# PIC32MX550F256L register map
Vendor: Microchip
Registers are 32-bit, read-write, reset 0x0 unless marked. A register's access mark holds for its fields unless they carry their own. Addresses are absolute, and some are shared; only a register's first bit layout is shown; [hi:lo] are bit positions; {n}, {i} and the like mark numbered series.

## CMP2
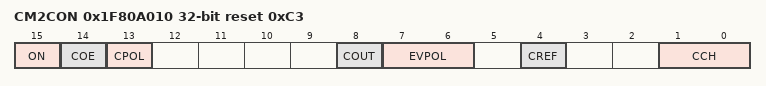
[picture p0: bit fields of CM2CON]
0x1F80A010 CM2CON reset 0xC3
  [15] ON, [14] COE, [13] CPOL, [8] COUT, [7:6] EVPOL, [4] CREF, [1:0] CCH

## CMP3
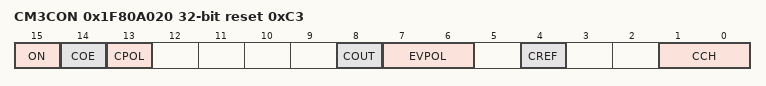
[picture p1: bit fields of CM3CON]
0x1F80A020 CM3CON reset 0xC3
  [15] ON, [14] COE, [13] CPOL, [8] COUT, [7:6] EVPOL, [4] CREF, [1:0] CCH

## cmp_control_pb
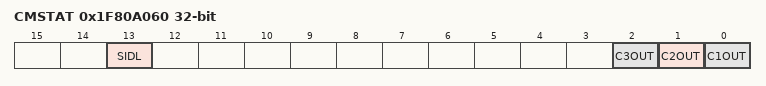
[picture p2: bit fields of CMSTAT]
0x1F80A060 CMSTAT reset not defined — (power-on value ------------------------00---x00)
  [13] SIDL, [2] C3OUT, [1] C2OUT ro, [0] C1OUT ro

## CTMU
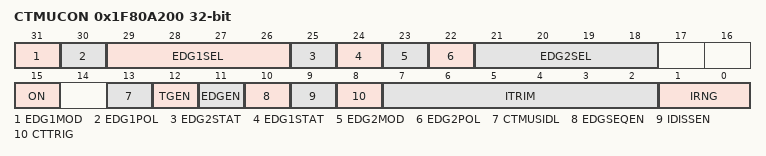
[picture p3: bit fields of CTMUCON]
0x1F80A200 CTMUCON
  [31] EDG1MOD, [30] EDG1POL, [29:26] EDG1SEL, [25] EDG2STAT, [24] EDG1STAT, [23] EDG2MOD, [22] EDG2POL, [21:18] EDG2SEL, [15] ON, [13] CTMUSIDL, [12] TGEN, [11] EDGEN, [10] EDGSEQEN, [9] IDISSEN, [8] CTTRIG, [7:2] ITRIM, [1:0] IRNG

## OSC
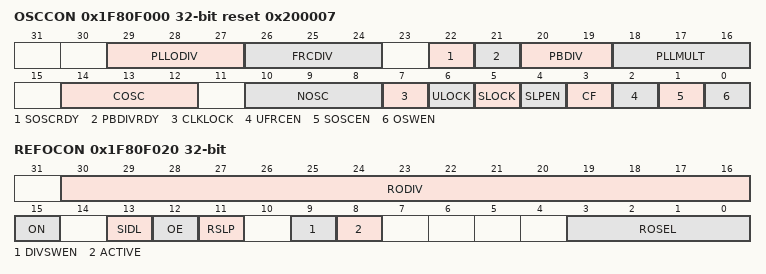
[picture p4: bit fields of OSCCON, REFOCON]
0x1F80F000 OSCCON reset 0x200007
  [29:27] PLLODIV, [26:24] FRCDIV, [22] SOSCRDY, [21] PBDIVRDY, [20:19] PBDIV, [18:16] PLLMULT, [14:12] COSC, [10:8] NOSC, [7] CLKLOCK, [6] ULOCK, [5] SLOCK, [4] SLPEN, [3] CF, [2] UFRCEN, [1] SOSCEN, [0] OSWEN
0x1F80F010 OSCTUN
  [5:0] TUN
0x1F80F020 REFOCON reset not defined — (power-on value -xxxxxxxxxxxxxxxxxxxxxxxx---xxxx)
  [30:16] RODIV, [15] ON, [13] SIDL, [12] OE, [11] RSLP, [9] DIVSWEN, [8] ACTIVE, [3:0] ROSEL
0x1F80F030 REFOTRIM reset not defined — (power-on value xxxxxxxxx-----------------------)
  [31:23] ROTRIM

## CFG
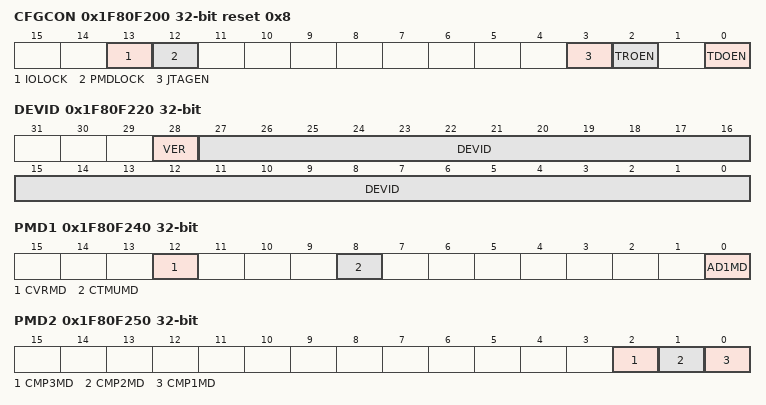
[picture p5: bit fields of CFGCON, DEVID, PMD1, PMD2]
0x1F80F200 CFGCON reset 0x8
  [13] IOLOCK, [12] PMDLOCK, [3] JTAGEN, [2] TROEN, [0] TDOEN
0x1F80F220 DEVID ro reset not defined — (power-on value xxxxxxxxxxxxxxxxxxxxxxxxxxxxxxxx)
  [28] VER, [27:0] DEVID
0x1F80F230 SYSKEY ro reset not defined — (power-on value xxxxxxxxxxxxxxxxxxxxxxxxxxxxxxxx)
0x1F80F240 PMD1
  [12] CVRMD, [8] CTMUMD, [0] AD1MD
0x1F80F250 PMD2
  [2] CMP3MD, [1] CMP2MD, [0] CMP1MD
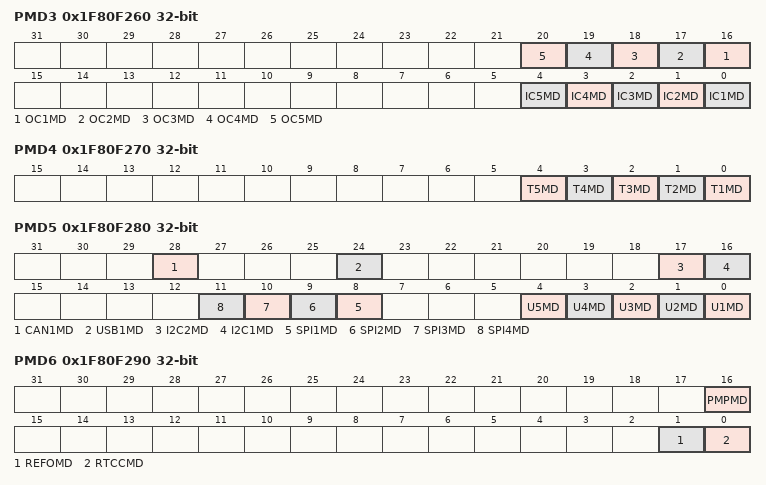
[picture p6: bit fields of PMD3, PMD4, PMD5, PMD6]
0x1F80F260 PMD3
  [n+15] OC{n}MD (n=1..5), [n-1] IC{n}MD (n=1..5)
0x1F80F270 PMD4
  [n-1] T{n}MD (n=1..5)
0x1F80F280 PMD5 reset not defined — (power-on value ---x---0------00----xx00---xxx00)
  [28] CAN1MD, [24] USB1MD, [17] I2C2MD, [16] I2C1MD, [n+7] SPI{n}MD (n=1..4), [n-1] U{n}MD (n=1..5)
0x1F80F290 PMD6
  [16] PMPMD, [1] REFOMD, [0] RTCCMD

## NVM
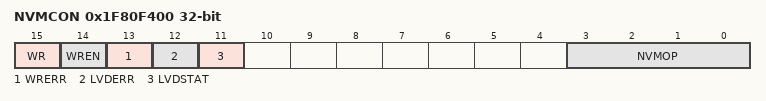
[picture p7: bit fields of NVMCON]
0x1F80F400 NVMCON
  [15] WR, [14] WREN, [13] WRERR, [12] LVDERR, [11] LVDSTAT, [3:0] NVMOP
0x1F80F410 NVMKEY wo
0x1F80F420 NVMADDR
0x1F80F430 NVMDATA
0x1F80F440 NVMSRCADDR

## RCON
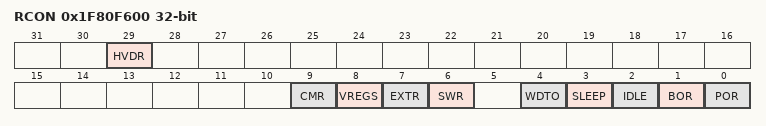
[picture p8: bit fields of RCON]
0x1F80F600 RCON reset not defined — (power-on value --x-------------------0000-00011)
  [29] HVDR, [9] CMR, [8] VREGS, [7] EXTR, [6] SWR, [4] WDTO, [3] SLEEP, [2] IDLE, [1] BOR, [0] POR
0x1F80F610 RSWRST
  [0] SWRST

## RPINRx
{0x1F80FA00+4i} INT{i}R (i=1..4)
  [3:0] INT{i}R
{0x1F80FA10+4i} T{i}CKR (i=2..5)
  [3:0] T{i}CKR
{0x1F80FA24+4i} IC{i}R (i=1..8)
  [3:0] IC{i}R
0x1F80FA48 OCFAR
  [3:0] OCFAR
0x1F80FA4C OCFBR
  [3:0] OCFBR
{0x1F80FA48+8i} U{i}RXR (i=1..6)
  [3:0] U{i}RXR
{0x1F80FA4C+8i} U{i}CTSR (i=1..6)
  [3:0] U{i}CTSR
{0x1F80FA78+0xC*i} SDI{i}R (i=1..6)
  [3:0] SDI{i}R
{0x1F80FA7C+0xC*i} SS{i}R (i=1..6)
  [3:0] SS{i}R
0x1F80FAC8 C1RXR
  [3:0] C1RXR
0x1F80FACC C2RXR
  [3:0] C2RXR
0x1F80FAD0 REFCLKIR
  [3:0] REFCLKIR
{0x1F80FACC+4i} REFI{i}R (i=2..4)
  [3:0] REFI{i}R

## RPORx
{0x1F80FB00+4i} RPA{i}R (i=0..15)
  [3:0] RPA{i}R
{0x1F80FB40+4i} RPB{i}R (i=0..15)
  [3:0] RPB{i}R
{0x1F80FB80+4i} RPC{i}R (i=0..15)
  [3:0] RPC{i}R
{0x1F80FBC0+4i} RPD{i}R (i=0..15)
  [3:0] RPD{i}R
{0x1F80FC00+4i} RPE{i}R (i=0..15)
  [3:0] RPE{i}R
{0x1F80FC40+4i} RPF{i}R (i=0..15)
  [3:0] RPF{i}R
{0x1F80FC80+4i} RPG{i}R (i=0..15)
  [3:0] RPG{i}R

## INT
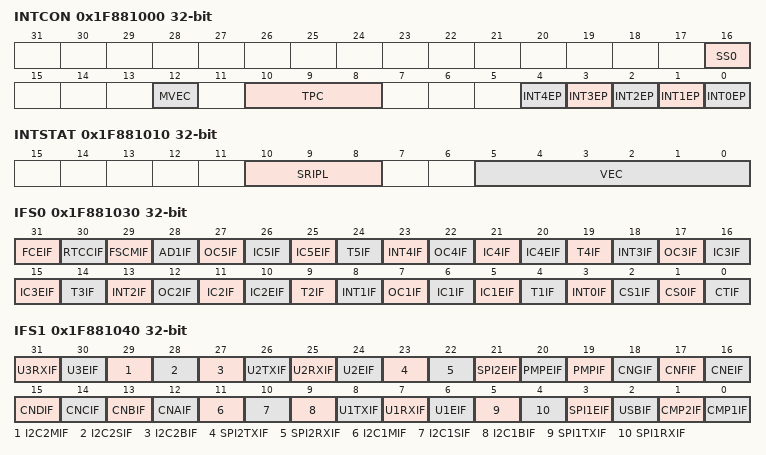
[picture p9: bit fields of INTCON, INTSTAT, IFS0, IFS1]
0x1F881000 INTCON
  [16] SS0, [12] MVEC, [10:8] TPC, [n] INT{n}EP (n=0..4)
0x1F881010 INTSTAT
  [10:8] SRIPL, [5:0] VEC
0x1F881020 IPTMR
0x1F881030 IFS0 reset not defined — (power-on value 00000x0000x0000x0000000000000000)
  [31] FCEIF, [30] RTCCIF, [29] FSCMIF, [28] AD1IF, [5n+2] OC{n}IF (n=1..5), [5n+1] IC{n}IF (n=1..5), [5n] IC{n}EIF (n=1..5), [5n-1] T{n}IF (n=1..5), [5n+3] INT{n}IF (n=0..4), [2] CS1IF, [1] CS0IF, [0] CTIF
0x1F881040 IFS1 reset not defined — (power-on value xxxxxx00xxxx00000000000000000000)
  [31] U3RXIF, [30] U3EIF, [29] I2C2MIF, [28] I2C2SIF, [27] I2C2BIF, [26] U2TXIF, [25] U2RXIF, [24] U2EIF, [23] SPI2TXIF, [22] SPI2RXIF, [21] SPI2EIF, [20] PMPEIF, [19] PMPIF, [18] CNGIF, [17] CNFIF, [16] CNEIF, [15] CNDIF, [14] CNCIF, [13] CNBIF, [12] CNAIF, [11] I2C1MIF, [10] I2C1SIF, [9] I2C1BIF, [8] U1TXIF, [7] U1RXIF, [6] U1EIF, [5] SPI1TXIF, [4] SPI1RXIF, [3] SPI1EIF, [2] USBIF, [1] CMP2IF, [0] CMP1IF
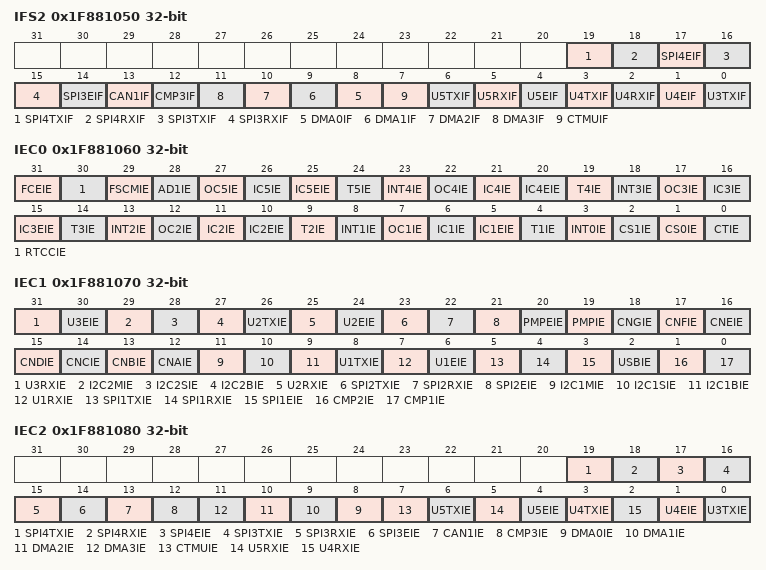
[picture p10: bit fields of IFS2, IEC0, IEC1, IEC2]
0x1F881050 IFS2
  [19] SPI4TXIF, [18] SPI4RXIF, [17] SPI4EIF, [16] SPI3TXIF, [15] SPI3RXIF, [14] SPI3EIF, [13] CAN1IF, [12] CMP3IF, [n+8] DMA{n}IF (n=0..3), [7] CTMUIF, [6] U5TXIF, [5] U5RXIF, [4] U5EIF, [3] U4TXIF, [2] U4RXIF, [1] U4EIF, [0] U3TXIF
0x1F881060 IEC0 reset not defined — (power-on value 00000x0000x0000x0000000000000000)
  [31] FCEIE, [30] RTCCIE, [29] FSCMIE, [28] AD1IE, [5n+2] OC{n}IE (n=1..5), [5n+1] IC{n}IE (n=1..5), [5n] IC{n}EIE (n=1..5), [5n-1] T{n}IE (n=1..5), [5n+3] INT{n}IE (n=0..4), [2] CS1IE, [1] CS0IE, [0] CTIE
0x1F881070 IEC1 reset not defined — (power-on value xxxxxx-0xxxx-0000000000000000000)
  [31] U3RXIE, [30] U3EIE, [29] I2C2MIE, [28] I2C2SIE, [27] I2C2BIE, [26] U2TXIE, [25] U2RXIE, [24] U2EIE, [23] SPI2TXIE, [22] SPI2RXIE, [21] SPI2EIE, [20] PMPEIE, [19] PMPIE, [18] CNGIE, [17] CNFIE, [16] CNEIE, [15] CNDIE, [14] CNCIE, [13] CNBIE, [12] CNAIE, [11] I2C1MIE, [10] I2C1SIE, [9] I2C1BIE, [8] U1TXIE, [7] U1RXIE, [6] U1EIE, [5] SPI1TXIE, [4] SPI1RXIE, [3] SPI1EIE, [2] USBIE, [1] CMP2IE, [0] CMP1IE
0x1F881080 IEC2
  [19] SPI4TXIE, [18] SPI4RXIE, [17] SPI4EIE, [16] SPI3TXIE, [15] SPI3RXIE, [14] SPI3EIE, [13] CAN1IE, [12] CMP3IE, [n+8] DMA{n}IE (n=0..3), [7] CTMUIE, [6] U5TXIE, [5] U5RXIE, [4] U5EIE, [3] U4TXIE, [2] U4RXIE, [1] U4EIE, [0] U3TXIE
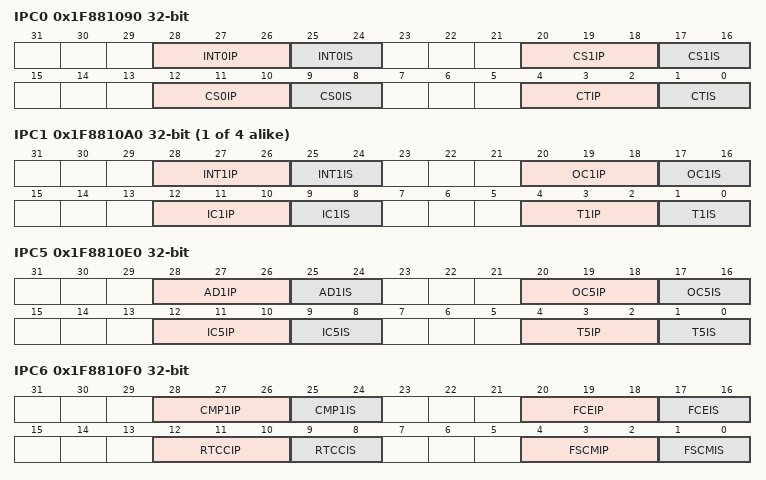
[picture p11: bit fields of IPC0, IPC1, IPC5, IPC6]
0x1F881090 IPC0
  [28:26] INT0IP, [25:24] INT0IS, [20:18] CS1IP, [17:16] CS1IS, [12:10] CS0IP, [9:8] CS0IS, [4:2] CTIP, [1:0] CTIS
{0x1F881090+0x10*i} IPC{i} (i=1..4)
  [28:26] INT{i}IP, [25:24] INT{i}IS, [20:18] OC{i}IP, [17:16] OC{i}IS, [12:10] IC{i}IP, [9:8] IC{i}IS, [4:2] T{i}IP, [1:0] T{i}IS
0x1F8810E0 IPC5
  [28:26] AD1IP, [25:24] AD1IS, [20:18] OC5IP, [17:16] OC5IS, [12:10] IC5IP, [9:8] IC5IS, [4:2] T5IP, [1:0] T5IS
0x1F8810F0 IPC6
  [28:26] CMP1IP, [25:24] CMP1IS, [20:18] FCEIP, [17:16] FCEIS, [12:10] RTCCIP, [9:8] RTCCIS, [4:2] FSCMIP, [1:0] FSCMIS
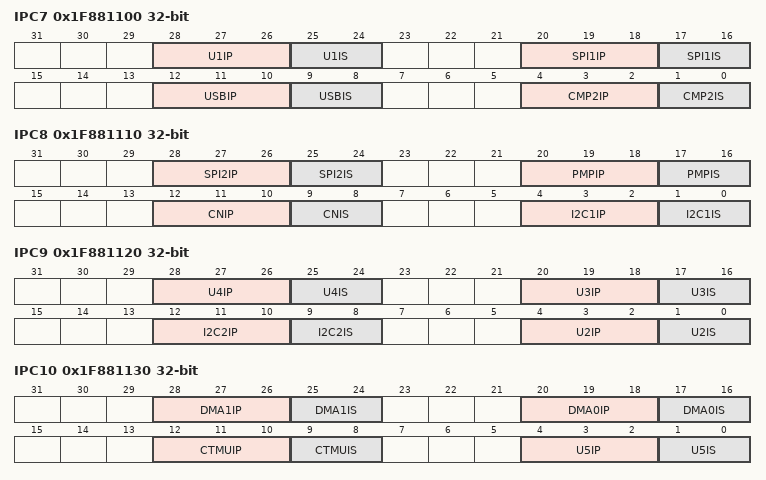
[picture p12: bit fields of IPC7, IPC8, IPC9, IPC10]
0x1F881100 IPC7
  [28:26] U1IP, [25:24] U1IS, [20:18] SPI1IP, [17:16] SPI1IS, [12:10] USBIP, [9:8] USBIS, [4:2] CMP2IP, [1:0] CMP2IS
0x1F881110 IPC8
  [28:26] SPI2IP, [25:24] SPI2IS, [20:18] PMPIP, [17:16] PMPIS, [12:10] CNIP, [9:8] CNIS, [4:2] I2C1IP, [1:0] I2C1IS
0x1F881120 IPC9
  [28:26] U4IP, [25:24] U4IS, [20:18] U3IP, [17:16] U3IS, [12:10] I2C2IP, [9:8] I2C2IS, [4:2] U2IP, [1:0] U2IS
0x1F881130 IPC10
  [28:26] DMA1IP, [25:24] DMA1IS, [20:18] DMA0IP, [17:16] DMA0IS, [12:10] CTMUIP, [9:8] CTMUIS, [4:2] U5IP, [1:0] U5IS
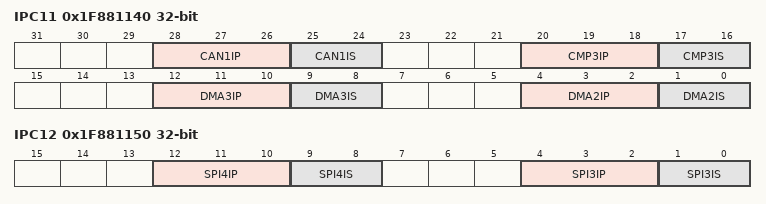
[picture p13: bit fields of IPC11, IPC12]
0x1F881140 IPC11
  [28:26] CAN1IP, [25:24] CAN1IS, [20:18] CMP3IP, [17:16] CMP3IS, [12:10] DMA3IP, [9:8] DMA3IS, [4:2] DMA2IP, [1:0] DMA2IS
0x1F881150 IPC12
  [12:10] SPI4IP, [9:8] SPI4IS, [4:2] SPI3IP, [1:0] SPI3IS
